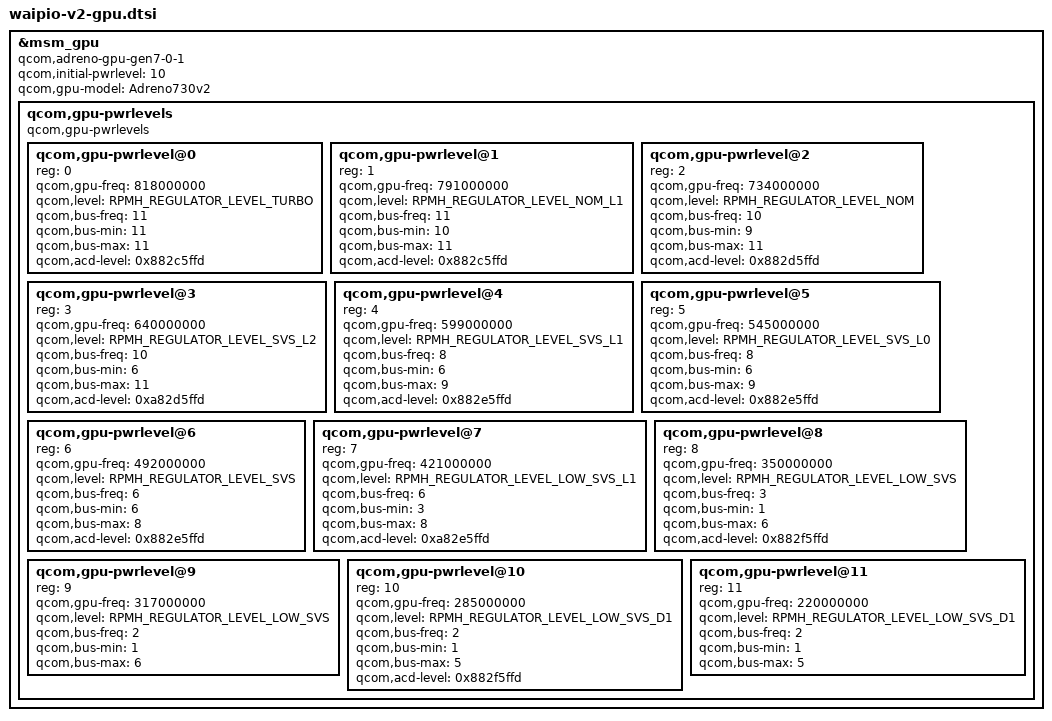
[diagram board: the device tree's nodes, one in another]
&msm_gpu {

	compatible = "qcom,adreno-gpu-gen7-0-1", "qcom,kgsl-3d0";

	qcom,initial-pwrlevel = <10>;

	qcom,gpu-model = "Adreno730v2";

	qcom,gpu-pwrlevels {
		#address-cells = <1>;
		#size-cells = <0>;

		compatible = "qcom,gpu-pwrlevels";

		qcom,gpu-pwrlevel@0 {
			reg = <0>;
			qcom,gpu-freq = <818000000>;
			qcom,level = <RPMH_REGULATOR_LEVEL_TURBO>;

			qcom,bus-freq = <11>;
			qcom,bus-min = <11>;
			qcom,bus-max = <11>;

			qcom,acd-level = <0x882c5ffd>;
		};

		qcom,gpu-pwrlevel@1 {
			reg = <1>;
			qcom,gpu-freq = <791000000>;
			qcom,level = <RPMH_REGULATOR_LEVEL_NOM_L1>;

			qcom,bus-freq = <11>;
			qcom,bus-min = <10>;
			qcom,bus-max = <11>;

			qcom,acd-level = <0x882c5ffd>;
		};

		qcom,gpu-pwrlevel@2 {
			reg = <2>;
			qcom,gpu-freq = <734000000>;
			qcom,level = <RPMH_REGULATOR_LEVEL_NOM>;

			qcom,bus-freq = <10>;
			qcom,bus-min = <9>;
			qcom,bus-max = <11>;

			qcom,acd-level = <0x882d5ffd>;
		};

		qcom,gpu-pwrlevel@3 {
			reg = <3>;
			qcom,gpu-freq = <640000000>;
			qcom,level = <RPMH_REGULATOR_LEVEL_SVS_L2>;

			qcom,bus-freq = <10>;
			qcom,bus-min = <6>;
			qcom,bus-max = <11>;

			qcom,acd-level = <0xa82d5ffd>;
		};

		qcom,gpu-pwrlevel@4 {
			reg = <4>;
			qcom,gpu-freq = <599000000>;
			qcom,level = <RPMH_REGULATOR_LEVEL_SVS_L1>;

			qcom,bus-freq = <8>;
			qcom,bus-min = <6>;
			qcom,bus-max = <9>;

			qcom,acd-level = <0x882e5ffd>;
		};

		qcom,gpu-pwrlevel@5 {
			reg = <5>;
			qcom,gpu-freq = <545000000>;
			qcom,level = <RPMH_REGULATOR_LEVEL_SVS_L0>;

			qcom,bus-freq = <8>;
			qcom,bus-min = <6>;
			qcom,bus-max = <9>;

			qcom,acd-level = <0x882e5ffd>;
		};

		qcom,gpu-pwrlevel@6 {
			reg = <6>;
			qcom,gpu-freq = <492000000>;
			qcom,level = <RPMH_REGULATOR_LEVEL_SVS>;

			qcom,bus-freq = <6>;
			qcom,bus-min = <6>;
			qcom,bus-max = <8>;

			qcom,acd-level = <0x882e5ffd>;
		};

		qcom,gpu-pwrlevel@7 {
			reg = <7>;
			qcom,gpu-freq = <421000000>;
			qcom,level = <RPMH_REGULATOR_LEVEL_LOW_SVS_L1>;

			qcom,bus-freq = <6>;
			qcom,bus-min = <3>;
			qcom,bus-max = <8>;

			qcom,acd-level = <0xa82e5ffd>;
		};

		qcom,gpu-pwrlevel@8 {
			reg = <8>;
			qcom,gpu-freq = <350000000>;
			qcom,level = <RPMH_REGULATOR_LEVEL_LOW_SVS>;

			qcom,bus-freq = <3>;
			qcom,bus-min = <1>;
			qcom,bus-max = <6>;

			qcom,acd-level = <0x882f5ffd>;
		};

		qcom,gpu-pwrlevel@9 {
			reg = <9>;
			qcom,gpu-freq = <317000000>;
			qcom,level = <RPMH_REGULATOR_LEVEL_LOW_SVS>;

			qcom,bus-freq = <2>;
			qcom,bus-min = <1>;
			qcom,bus-max = <6>;
		};

		qcom,gpu-pwrlevel@10 {
			reg = <10>;
			qcom,gpu-freq = <285000000>;
			qcom,level = <RPMH_REGULATOR_LEVEL_LOW_SVS_D1>;

			qcom,bus-freq = <2>;
			qcom,bus-min = <1>;
			qcom,bus-max = <5>;

			qcom,acd-level = <0x882f5ffd>;
		};

		qcom,gpu-pwrlevel@11 {
			reg = <11>;
			qcom,gpu-freq = <220000000>;
			qcom,level = <RPMH_REGULATOR_LEVEL_LOW_SVS_D1>;

			qcom,bus-freq = <2>;
			qcom,bus-min = <1>;
			qcom,bus-max = <5>;
		};
	};
};
